# TC80_VXX register map
Vendor: Geneal MCU Ltd.; Series: ARMCM0; File version: 1.2
CPU: CM0 r0p0, little endian, no MPU, no FPU, 2 interrupt priority bits
Registers are 32-bit, read-write, reset 0x0 unless marked. A register's access mark holds for its fields unless they carry their own. Offsets are from the block's base; [hi:lo] are bit positions; 'fields as' and 'values as' point back to an identical list.

## TIM0 — 16 bits Timer / Counter
Base 0x49000000
Same registers: TIM2 0x49000800
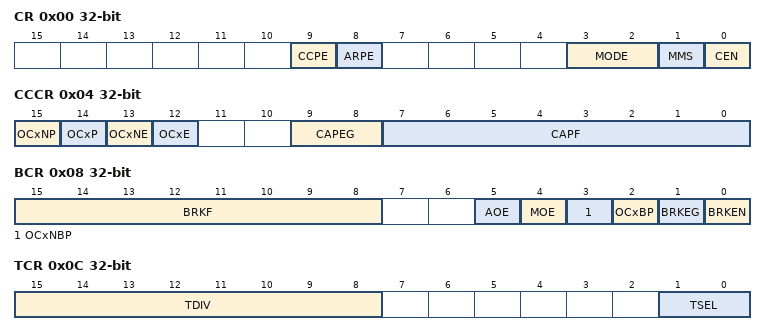
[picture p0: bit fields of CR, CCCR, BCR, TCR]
0x00 CR — Control register
  [9] CCPE — Capture/Compare pre-reload control
    0=Disable (Capture/Compare pre-reload is not used); 1=Enable (Capture/Compare pre-reload is used)
  [8] ARPE — Auto reload pre-enable
    0=Disable (Auto pre-reload is not used); 1=Enable (Auto pre-reload is used)
  [3:2] MODE — Running mode select
    0=Count_Mode (Timer counts); 1=Capture_Mode (Timer capture input signal); 2=Compare_Mode (Timer campare and output signal); 3=One_Pulse_Mode (Timer output one pulse signal)
  [1] MMS — Master mode select
    0=Master_Mode (Select master mode); 1=Slave_Mode (Select slave mode)
  [0] CEN — Enable
    0=Disable (Timer is disabled); 1=Enable (Timer is enabled)
0x04 CCCR — Capture/Compare control register
  [15] OCxNP — OCxN output polarity select
    0=Equal (Select output same as ref signal); 1=Oppsite (Select output oppsite as ref signal)
  [14] OCxP — OCx output polarity select
    values as OCxNP
  [13] OCxNE — OCxN output enable
    0=Disable (Compare output disabled); 1=Enable (Compare output enable)
  [12] OCxE — OCx output enable
    0=Disable (Compare output disabled); 1=Enable (Compare output enabled)
  [9:8] CAPEG — Break edge select
    0=Posedge (Poseedge active); 1=Negedge active; 2=Bothedge (Posedge and negedge both active); 3=No_Active (No edge active)
  [7:0] CAPF — Capture filter configuration
0x08 BCR (reset mask 0xFF1F) — Break control register
  [15:8] BRKF — Break filter configutaion
  [5] AOE — Automatic output enable
    0=Disable (MOE can be set only by software); 1=Enable (MOE can be set by software or automatically if break input is not be active)
  [4] MOE — Main output enable
    0=Disable (OCx and OCxN outputs are disabled); 1=Enable (OCx and OCxN outputs are enabled)
  [3] OCxNBP — OCxN output polarity select
    0=Low (Select low level after break); 1=High (Select high level after break)
  [2] OCxBP — OCx output polarity select
    values as OCxNBP
  [1] BRKEG — Break edge select
    0=Posedge (Poseedge active); 1=Negedge active
  [0] BRKEN — Break enable
    0=Disable (Break disabled); 1=Enable (Break enabled)
0x0C TCR — Trigger control register
  [15:8] TDIV — Trigger divsion
  [1:0] TSEL — Trigger souce select
    0=Both (Compare/Capture and Count interrupt both active trigger); 1=CC (Compare/Capture interrupt active trigger); 2=Count interrupt active trigger; 3=Disable (Trigger disabled)
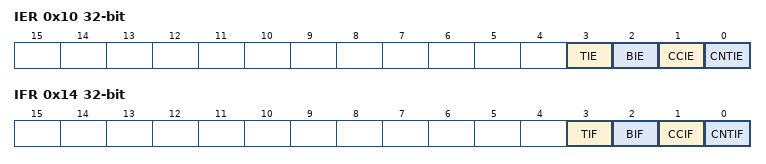
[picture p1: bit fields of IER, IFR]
0x10 IER — Interrupt enable register
  [3] TIE — Trigger interrupt enable
    0=Disable (Trigger interrupt enabled); 1=Enable (Trigger interrupt disabled)
  [2] BIE — Break interrupt enable
    0=Disable (Break interrupt enabled); 1=Enable (Break interrupt disabled)
  [1] CCIE — Compare/Capture interrupt enable
    0=Disable (Compare/Capture interrupt enabled); 1=Enable (Compare/Capture interrupt disabled)
  [0] CNTIE — Count interrupt enable
    0=Disable (Count interrupt enabled); 1=Enable (Count interrupt disabled)
0x14 IFR — Interrupt flag register
  [3] TIF — Trigger interrupt flag
    0=No_Trigger (Trigger interrupt has no occured); 1=Trigger_Occured (Trigger interrupt has occured)
  [2] BIF — Break interrupt flag
    0=No_Break (Break interrupt has no occured); 1=Break_Occured (Break interrupt has occured)
  [1] CCIF — Compare/Capture interrupt flag
    0=No_CC (Compare/Capture interrupt has no occured); 1=CC_Occured (Compare/Capture interrupt has occured)
  [0] CNTIF — Count interrupt flag
    0=No_Overflow (Overflow interrupt has no occured); 1=Overflow_Occured (Overflow interrupt has occured)
0x18 CNT (reset mask 0xFFFF) — The counter register reflects the actual value of the timer/counter
0x1C DIV (reset mask 0xFFFF) — The DIV register set run frequency as PCLK/DIV
0x20 ARR reset 0xFFFF (reset mask 0xFFFF) — The ARR register stroes the value to be loaded in the actual auto-reload register
0x24 CCR (reset mask 0xFFFF) — The CCR register stores the Value for Compare/Capture happend
0x28 DTG (reset mask 0xFFFF) — Dead time generate register

## TIM1 — 16 bits Timer / Counter
Base 0x49000400
Registers as TIM0; these are added or differ:
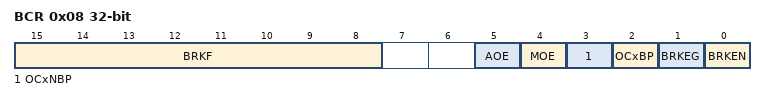
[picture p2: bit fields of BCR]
0x08 BCR (reset mask 0xFF1F) — Break control register
  [15:8] BRKF — Break filter configutaion
  [5] AOE — Automatic output enable
    0=Disable (MOE can be set only by software); 1=Enable (MOE can be set by software or automatically if break input is not be active)
  [4] MOE — Main output enable
    0=Disable (OCx and OCxN outputs are disabled); 1=Enable (OCx and OCxN outputs are enabled)
  [3] OCxNBP — OCxN output polarity select
    0=Low (Select low level after break); 1=High (Select high level after break)
  [2] OCxBP — OCx output polarity select
    values as OCxNBP
  [1] BRKEG — Break edge select
    0=Low (Low level active); 1=High level active
  [0] BRKEN — Break enable
    0=Disable (Break disabled); 1=Enable (Break enabled)
